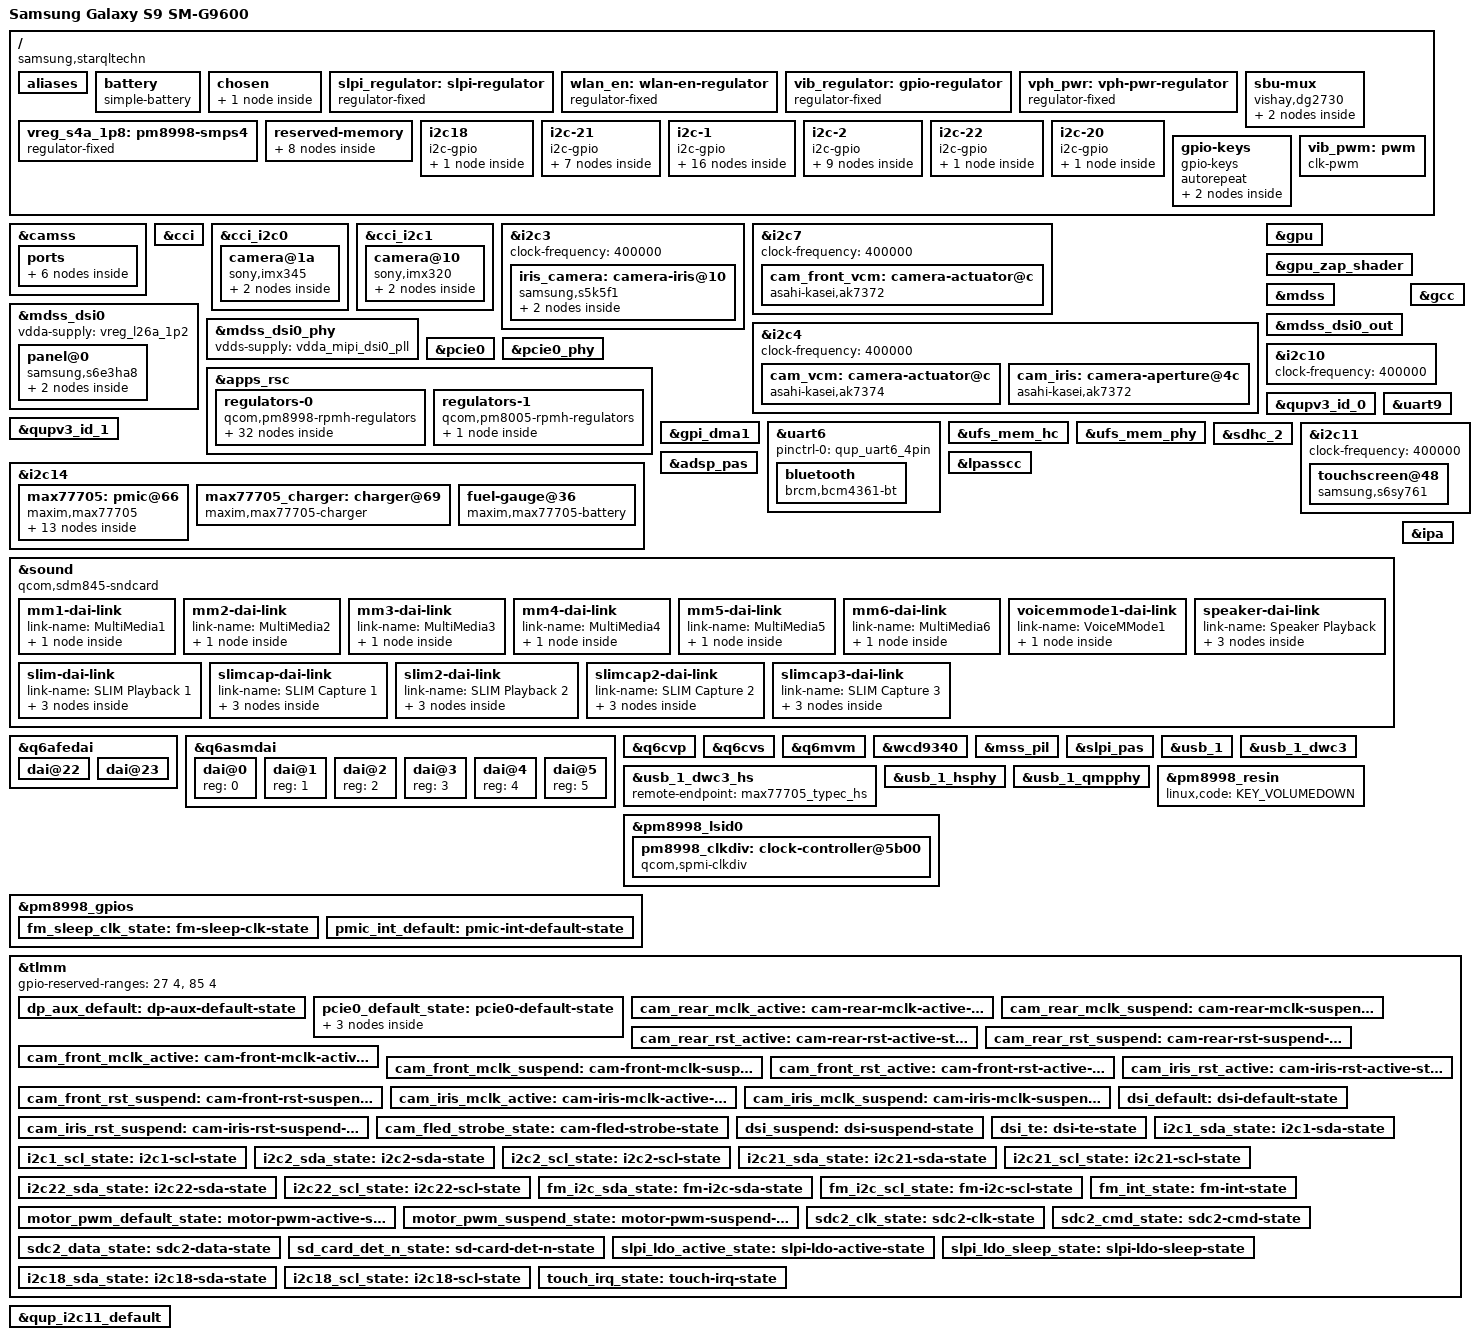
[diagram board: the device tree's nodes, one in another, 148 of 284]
// SPDX-License-Identifier: GPL-2.0
/*
 * SDM845 Samsung S9 (SM-G9600) (starqltechn / star2qltechn) common device tree source
 *
 * Copyright (c) 2020, The Linux Foundation. All rights reserved.
 */

/dts-v1/;

#include <dt-bindings/input/linux-event-codes.h>
#include <dt-bindings/gpio/gpio.h>
#include <dt-bindings/leds/common.h>
#include <dt-bindings/media/video-interfaces.h>
#include <dt-bindings/regulator/qcom,rpmh-regulator.h>
#include <dt-bindings/sound/qcom,q6afe.h>
#include <dt-bindings/sound/qcom,q6asm.h>
#include <dt-bindings/sound/qcom,wcd934x.h>
#include <dt-bindings/sound/qcom,q6voice.h>

#include "sdm845.dtsi"
#include "pm8998.dtsi"
#include "sdm845-wcd9340.dtsi"

/delete-node/ &rmtfs_mem;
/delete-node/ &spss_mem;
/delete-node/ &adsp_mem;

/ {
	chassis-type = "handset";
	model = "Samsung Galaxy S9 SM-G9600";
	compatible = "samsung,starqltechn", "qcom,sdm845";

	aliases {
		serial0 = &uart9;
		serial1 = &uart6;
	};

	battery: battery {
		compatible = "simple-battery";
		constant-charge-current-max-microamp = <2150000>;
		charge-full-design-microamp-hours = <3000000>;

		over-voltage-threshold-microvolt = <4500000>;
		voltage-min-design-microvolt = <3400000>;
		voltage-max-design-microvolt = <4350000>;
	};

	chosen {
		#address-cells = <2>;
		#size-cells = <2>;
		ranges;

		framebuffer: framebuffer-0 {
			compatible = "simple-framebuffer";
			memory-region = <&framebuffer_mem>;
			width = <1440>;
			height = <2960>;
			stride = <(1440 * 4)>;
			format = "a8r8g8b8";
			vci-supply = <&s2dos05_ldo4>;
			vddr-supply = <&s2dos05_buck>;
			vdd3-supply = <&s2dos05_ldo1>;
		};
	};

	slpi_regulator: slpi-regulator {
		compatible = "regulator-fixed";
		pinctrl-0 = <&slpi_ldo_active_state>;
		pinctrl-names = "default";

		regulator-always-on;
		regulator-boot-on;
		regulator-min-microvolt = <1800000>;
		regulator-max-microvolt = <1800000>;
		regulator-name = "slpi";

		enable-active-high;
		gpio = <&tlmm 8 GPIO_ACTIVE_HIGH>;
	};

	wlan_en: wlan-en-regulator {
		compatible = "regulator-fixed";

		regulator-name = "wlan-en";
		regulator-min-microvolt = <3300000>;
		regulator-max-microvolt = <3300000>;

		enable-active-high;
		gpio = <&tlmm 99 GPIO_ACTIVE_HIGH>;
		startup-delay-us = <200000>;
	};

	vib_regulator: gpio-regulator {
		compatible = "regulator-fixed";

		regulator-name = "haptic";
		regulator-min-microvolt = <1800000>;
		regulator-max-microvolt = <1800000>;

		gpio = <&pm8998_gpios 18 GPIO_ACTIVE_HIGH>;
		enable-active-high;

		regulator-boot-on;
	};

	vph_pwr: vph-pwr-regulator {
		compatible = "regulator-fixed";
		regulator-name = "vph_pwr";
		regulator-min-microvolt = <3700000>;
		regulator-max-microvolt = <3700000>;
	};

	/*
	 * Steers the SBU pair onto the DisplayPort AUX lines, so that AUX
	 * follows the cable orientation. The vendor kernel calls this the EDP
	 * AUX switch and drives the enable low to connect it.
	 */
	sbu-mux {
		compatible = "vishay,dg2730", "gpio-sbu-mux";

		enable-gpios = <&tlmm 7 GPIO_ACTIVE_LOW>;
		select-gpios = <&tlmm 100 GPIO_ACTIVE_HIGH>;

		pinctrl-0 = <&dp_aux_default>;
		pinctrl-names = "default";

		mode-switch;
		orientation-switch;

		port {
			sbu_mux_in: endpoint {
				remote-endpoint = <&max77705_typec_sbu>;
			};
		};
	};

	/*
	 * Apparently RPMh does not provide support for PM8998 S4 because it
	 * is always-on; model it as a fixed regulator.
	 */
	vreg_s4a_1p8: pm8998-smps4 {
		compatible = "regulator-fixed";
		regulator-name = "vreg_s4a_1p8";

		regulator-min-microvolt = <1800000>;
		regulator-max-microvolt = <1800000>;

		regulator-always-on;
		regulator-boot-on;

		vin-supply = <&vph_pwr>;
	};

	reserved-memory {
		framebuffer_mem: memory@9d400000 {
			reg = <0x0 0x9d400000 0x0 0x02400000>;
			no-map;
		};

		memory@a1300000 {
			compatible = "ramoops";
			reg = <0x0 0xa1300000 0x0 0x100000>;
			record-size = <0x40000>;
			console-size = <0x40000>;
			ftrace-size = <0x40000>;
			pmsg-size = <0x40000>;
		};

		/*
		 * It seems like reserving the old rmtfs_mem region is also needed to prevent
		 * random crashes which are most likely modem related, more testing needed.
		 */
		removed_region: removed-region@88f00000 {
			reg = <0 0x88f00000 0 0x1c00000>;
			no-map;
		};

		/*
		 * This device gives SLPI 16 MiB rather than the SoC default of
		 * 20 MiB, and puts SPSS directly after it. Without shrinking
		 * SLPI to match, the two regions overlap and the kernel says so
		 * at boot.
		 */
		slpi_mem: slpi@96700000 {
			reg = <0 0x96700000 0 0x1000000>;
			no-map;
		};

		spss_mem: spss@97700000 {
			reg = <0 0x97700000 0 0x100000>;
			no-map;
		};

		fb_mem: memory@95800000 {
			reg = <0 0x95800000 0 0x500000>;
			no-map;
		};

		adsp_mem: memory@97800000 {
			reg = <0 0x97800000 0 0x2000000>;
			no-map;
		};

		rmtfs_mem: rmtfs-mem@fde00000 {
			compatible = "qcom,rmtfs-mem";
			reg = <0 0xfde00000 0 0x202000>;
			qcom,use-guard-pages;
			no-map;

			qcom,client-id = <1>;
			qcom,vmid = <QCOM_SCM_VMID_MSS_MSA>;
		};
	};

	i2c18 {
		compatible = "i2c-gpio";
		sda-gpios = <&tlmm 62 GPIO_ACTIVE_HIGH>;
		scl-gpios = <&tlmm 63 GPIO_ACTIVE_HIGH>;
		i2c-gpio,delay-us = <2>;
		pinctrl-0 = <&i2c18_sda_state &i2c18_scl_state>;
		pinctrl-names = "default";
		#address-cells = <1>;
		#size-cells = <0>;

		max98512_codec: max98512@39 {
			compatible = "maxim,max98512";
			#sound-dai-cells = <0>;
			reg = <0x39>;
			maxim,spk-gain = <0x5>;
			maxim,spk-gain-rcv = <0x1>;
			maxim,digital-gain-rcv = <0x34>;
			maxim,sysclk = <0xbb8000>;
			maxim,vmon_slot = <0x1>;
			maxim,platform_info = <0x1 0x1006 0x10001062 0x1ff1020b 0x0 0x33>;
			maxim,boost_step = <0xf 0xf 0xf 0xf 0xf 0xf 0xf 0xf 0xf 0xf 0xf 0xf 0xf 0xf 0x2 0x0>;
			maxim,registers-of-amp = <0x1f 0x0 0x21 0xc0 0x2d 0x14 0x2f 0x0>;
			maxim,sub_reg = <0x3a>;
			maxim,mono_stereo = <0x1>;
			interleave_mode = <0x1>;
		};
	};

	i2c-21 {
		compatible = "i2c-gpio";
		sda-gpios = <&tlmm 127 (GPIO_ACTIVE_HIGH | GPIO_OPEN_DRAIN)>;
		scl-gpios = <&tlmm 128 (GPIO_ACTIVE_HIGH | GPIO_OPEN_DRAIN)>;
		i2c-gpio,delay-us = <2>;
		pinctrl-0 = <&i2c21_sda_state &i2c21_scl_state>;
		pinctrl-names = "default";
		#address-cells = <1>;
		#size-cells = <0>;

		pmic@60 {
			compatible = "samsung,s2dos05";
			reg = <0x60>;

			regulators {
				s2dos05_ldo1: ldo1 {
					regulator-active-discharge = <1>;
					regulator-enable-ramp-delay = <12000>;
					regulator-min-microvolt = <1500000>;
					regulator-max-microvolt = <2000000>;
					regulator-name = "ldo1";
				};

				s2dos05_ldo2: ldo2 {
					regulator-active-discharge = <1>;
					regulator-boot-on;
					regulator-enable-ramp-delay = <12000>;
					regulator-min-microvolt = <1800000>;
					regulator-max-microvolt = <1800000>;
					regulator-name = "ldo2";
				};

				s2dos05_ldo3: ldo3 {
					regulator-active-discharge = <1>;
					regulator-boot-on;
					regulator-enable-ramp-delay = <12000>;
					regulator-min-microvolt = <3000000>;
					regulator-max-microvolt = <3000000>;
					regulator-name = "ldo3";
				};

				s2dos05_ldo4: ldo4 {
					regulator-active-discharge = <1>;
					regulator-enable-ramp-delay = <12000>;
					regulator-min-microvolt = <2700000>;
					regulator-max-microvolt = <3775000>;
					regulator-name = "ldo4";
				};

				s2dos05_buck: buck {
					regulator-active-discharge = <1>;
					regulator-enable-ramp-delay = <12000>;
					regulator-min-microvolt = <850000>;
					regulator-max-microvolt = <2100000>;
					regulator-name = "buck";
				};
			};
		};
	};

	/*
	 * Front camera sub-PMIC bus. The s2mpb02 also carries two rails for
	 * the rear camera's actuator and OIS, plus a flash/torch LED
	 * controller that is not modelled yet.
	 *
	 * Only the rails with known camera consumers are described. The
	 * bucks and buck-boost feed loads that have not been identified, and
	 * declaring a fixed voltage for them would make the regulator core
	 * reprogram whatever the bootloader left in place.
	 */
	i2c-1 {
		compatible = "i2c-gpio";
		sda-gpios = <&tlmm 23 (GPIO_ACTIVE_HIGH | GPIO_OPEN_DRAIN)>;
		scl-gpios = <&tlmm 24 (GPIO_ACTIVE_HIGH | GPIO_OPEN_DRAIN)>;
		i2c-gpio,delay-us = <2>;
		pinctrl-0 = <&i2c1_sda_state &i2c1_scl_state>;
		pinctrl-names = "default";
		#address-cells = <1>;
		#size-cells = <0>;

		pmic@59 {
			compatible = "samsung,s2mpb02";
			reg = <0x59>;

			/*
			 * Both FLED channels are driven over I2C, so hold the
			 * three external strobe pins low: FLASH_EN1 (gpio22)
			 * and TORCH_EN1 (gpio21) for the rear flash, and
			 * IRIS_EN (gpio43) for the illuminator. The vendor
			 * asserts IRIS_EN for the whole iris session and lets
			 * the pulse-width registers shape the light, which is
			 * the fallback if I2C strobing alone does not light it.
			 */
			pinctrl-0 = <&cam_fled_strobe_state>;
			pinctrl-names = "default";

			/*
			 * Currents and timeouts are the ones the vendor
			 * programs: 1000mA/500ms flash and 180mA torch on the
			 * rear LED, 500mA/250ms and 300mA on the illuminator.
			 */
			leds {
				#address-cells = <1>;
				#size-cells = <0>;

				s2mpb02_flash: led@0 {
					reg = <0>;
					color = <LED_COLOR_ID_WHITE>;
					function = LED_FUNCTION_FLASH;
					led-max-microamp = <180000>;
					flash-max-microamp = <1000000>;
					flash-max-timeout-us = <500000>;
				};

				/*
				 * Deliberately not LED_FUNCTION_FLASH: mobile
				 * shells look for a flashlight by matching LED
				 * class names against *:flash* and *:torch*,
				 * and this one emits infrared. Naming it
				 * "flash" makes the shell offer an invisible
				 * torch that only drains the battery.
				 */
				s2mpb02_ir: led@1 {
					reg = <1>;
					color = <LED_COLOR_ID_IR>;
					function = "illuminator";
					led-max-microamp = <300000>;
					flash-max-microamp = <500000>;
					flash-max-timeout-us = <250000>;
				};
			};

			regulators {
				s2mpb02_l5: ldo5 {
					regulator-name = "cam_front_vdig";
					regulator-min-microvolt = <1050000>;
					regulator-max-microvolt = <1050000>;
				};

				s2mpb02_l6: ldo6 {
					regulator-name = "cam_front_vio";
					regulator-min-microvolt = <1800000>;
					regulator-max-microvolt = <1800000>;
				};

				s2mpb02_l10: ldo10 {
					regulator-name = "cam_v_custom3";
					regulator-min-microvolt = <1800000>;
					regulator-max-microvolt = <1800000>;
				};

				s2mpb02_l13: ldo13 {
					regulator-name = "cam_front_vana";
					regulator-min-microvolt = <2800000>;
					regulator-max-microvolt = <2800000>;
				};

				s2mpb02_l14: ldo14 {
					regulator-name = "cam_vaf";
					regulator-min-microvolt = <3300000>;
					regulator-max-microvolt = <3300000>;
				};

				s2mpb02_l15: ldo15 {
					regulator-name = "cam_v_custom4";
					regulator-min-microvolt = <2800000>;
					regulator-max-microvolt = <2800000>;
				};

				s2mpb02_l16: ldo16 {
					regulator-name = "cam_front_vaf";
					regulator-min-microvolt = <2800000>;
					regulator-max-microvolt = <2800000>;
				};

				s2mpb02_l17: ldo17 {
					regulator-name = "cam_iris_vana";
					regulator-min-microvolt = <2800000>;
					regulator-max-microvolt = <2800000>;
				};

				/*
				 * BUCK1, BUCK2 and the buck-boost are the input
				 * rails the LDOs above regulate down from, so
				 * they have no consumer of their own and must
				 * stay on. The bootloader leaves them in
				 * pin-controlled mode at voltages that do not
				 * match the ones the vendor uses, so declare
				 * them here and let the core program them.
				 */
				s2mpb02_b1: buck1 {
					regulator-name = "cam_buck1";
					regulator-min-microvolt = <1300000>;
					regulator-max-microvolt = <1300000>;
					regulator-always-on;
				};

				s2mpb02_b2: buck2 {
					regulator-name = "cam_buck2";
					regulator-min-microvolt = <1300000>;
					regulator-max-microvolt = <1300000>;
					regulator-always-on;
				};

				s2mpb02_bb: bb {
					regulator-name = "cam_buckboost";
					regulator-min-microvolt = <3500000>;
					regulator-max-microvolt = <3500000>;
					regulator-always-on;
				};
			};
		};
	};

	/*
	 * Camera sub-PMIC bus. Supplies the rear camera rails; the sensor
	 * itself additionally draws two rails from the s2mpb02 on another
	 * bus, which are only needed for the actuator and OIS.
	 */
	i2c-2 {
		compatible = "i2c-gpio";
		sda-gpios = <&tlmm 11 (GPIO_ACTIVE_HIGH | GPIO_OPEN_DRAIN)>;
		scl-gpios = <&tlmm 74 (GPIO_ACTIVE_HIGH | GPIO_OPEN_DRAIN)>;
		i2c-gpio,delay-us = <2>;
		pinctrl-0 = <&i2c2_sda_state &i2c2_scl_state>;
		pinctrl-names = "default";
		#address-cells = <1>;
		#size-cells = <0>;

		pmic@56 {
			compatible = "samsung,s2mpb03";
			reg = <0x56>;

			regulators {
				s2mpb03_l1: ldo1 {
					regulator-name = "cam_vdig";
					regulator-min-microvolt = <1000000>;
					regulator-max-microvolt = <1000000>;
				};

				s2mpb03_l2: ldo2 {
					regulator-name = "cam_v_custom2";
					regulator-min-microvolt = <1100000>;
					regulator-max-microvolt = <1100000>;
					regulator-active-discharge = <1>;
				};

				s2mpb03_l3: ldo3 {
					regulator-name = "cam_vio";
					regulator-min-microvolt = <1800000>;
					regulator-max-microvolt = <1800000>;
				};

				s2mpb03_l4: ldo4 {
					regulator-name = "cam_v_custom10";
					regulator-min-microvolt = <1100000>;
					regulator-max-microvolt = <1100000>;
				};

				s2mpb03_l5: ldo5 {
					regulator-name = "cam_vana";
					regulator-min-microvolt = <3200000>;
					regulator-max-microvolt = <3200000>;
					regulator-soft-start;
				};

				s2mpb03_l6: ldo6 {
					regulator-name = "cam_v_custom1";
					regulator-min-microvolt = <2850000>;
					regulator-max-microvolt = <2850000>;
					regulator-soft-start;
				};

				s2mpb03_l7: ldo7 {
					regulator-name = "cam_v_custom5";
					regulator-min-microvolt = <2800000>;
					regulator-max-microvolt = <2800000>;
				};
			};
		};
	};

	/*
	 * GPIO expander bus. The PCAL6524 carries board control lines that are
	 * not routed to the SoC: the microSD and NFC enables, wireless charging
	 * and MST power, the fingerprint sensor's LDO and reset, and the
	 * heart-rate sensor's boost enable.
	 */
	i2c-22 {
		compatible = "i2c-gpio";
		sda-gpios = <&tlmm 123 (GPIO_ACTIVE_HIGH | GPIO_OPEN_DRAIN)>;
		scl-gpios = <&tlmm 124 (GPIO_ACTIVE_HIGH | GPIO_OPEN_DRAIN)>;
		i2c-gpio,delay-us = <2>;
		pinctrl-0 = <&i2c22_sda_state &i2c22_scl_state>;
		pinctrl-names = "default";
		#address-cells = <1>;
		#size-cells = <0>;

		gpio_expander: gpio@22 {
			compatible = "nxp,pcal6524";
			reg = <0x22>;

			gpio-controller;
			#gpio-cells = <2>;

			reset-gpios = <&tlmm 69 GPIO_ACTIVE_LOW>;
			vcc-supply = <&vreg_s4a_1p8>;

			gpio-line-names = "microsd-en", "", "", "wireless-charger-en",
					  "mst-pwr-en", "", "nfc-en", "nfc-firmware",
					  "", "", "", "",
					  "", "", "", "",
					  "", "", "fingerprint-ldo-en", "",
					  "fingerprint-reset", "", "fingerprint-vendor-id",
					  "hrm-boost-en";
		};
	};

	/*
	 * FM tuner bus. The Richwave RTC6213N takes its 32.768 kHz reference
	 * from pm8998 GPIO13 in func1 (sleep clock) mode, so that state is
	 * applied here alongside the bus pins -- the tuner does not answer
	 * without its clock running.
	 */
	i2c-20 {
		compatible = "i2c-gpio";
		sda-gpios = <&tlmm 103 GPIO_ACTIVE_HIGH>;
		scl-gpios = <&tlmm 104 GPIO_ACTIVE_HIGH>;
		i2c-gpio,delay-us = <2>;
		pinctrl-0 = <&fm_i2c_sda_state &fm_i2c_scl_state &fm_sleep_clk_state>;
		pinctrl-names = "default";
		#address-cells = <1>;
		#size-cells = <0>;

		tuner@64 {
			compatible = "richwave,rtc6213n";
			reg = <0x64>;

			interrupts-extended = <&tlmm 145 IRQ_TYPE_EDGE_FALLING>;
			pinctrl-0 = <&fm_int_state>;
			pinctrl-names = "default";

			/*
			 * BRING-UP: which of the three dividers actually lands
			 * on PMIC GPIO13 is not documented anywhere we have,
			 * so claim all three and let the driver enable them.
			 * Narrow this to the one that matters once the core
			 * comes up.
			 */
			clocks = <&pm8998_clkdiv 1>, <&pm8998_clkdiv 2>,
				 <&pm8998_clkdiv 3>;
			clock-names = "div1", "div2", "div3";
		};
	};

	gpio-keys {
		compatible = "gpio-keys";
		autorepeat;

		key-vol-up {
			label = "Volume Up";
			gpios = <&pm8998_gpios 6 GPIO_ACTIVE_LOW>;
			linux,code = <KEY_VOLUMEUP>;
			debounce-interval = <15>;
		};

		key-wink {
			label = "Bixby";
			gpios = <&pm8998_gpios 19 GPIO_ACTIVE_LOW>;
			linux,code = <KEY_ENTER>;
			debounce-interval = <15>;
		};
	};

	vib_pwm: pwm {
		compatible = "clk-pwm";
		#pwm-cells = <2>;
		assigned-clock-parents = <&rpmhcc RPMH_CXO_CLK>;
		assigned-clocks = <&gcc GCC_GP1_CLK_SRC>;
		clocks = <&gcc GCC_GP1_CLK>;
		pinctrl-0 = <&motor_pwm_default_state>;
		pinctrl-1 = <&motor_pwm_suspend_state>;
		pinctrl-names = "default", "suspend";
	};
};

&camss {
	vdda-phy-supply = <&vreg_l1a_0p875>;
	vdda-pll-supply = <&vreg_l26a_1p2>;

	status = "okay";

	ports {
		#address-cells = <1>;
		#size-cells = <0>;

		port@0 {
			reg = <0>;

			csiphy0_ep: endpoint {
				bus-type = <MEDIA_BUS_TYPE_CSI2_DPHY>;
				data-lanes = <0 1 2 3>;
				remote-endpoint = <&imx345_ep>;
			};
		};

		port@2 {
			reg = <2>;

			csiphy2_ep: endpoint {
				bus-type = <MEDIA_BUS_TYPE_CSI2_DPHY>;
				data-lanes = <0 1>;
				remote-endpoint = <&imx320_ep>;
			};
		};

		port@3 {
			reg = <3>;

			csiphy3_ep: endpoint {
				bus-type = <MEDIA_BUS_TYPE_CSI2_DPHY>;
				data-lanes = <0 1>;
				remote-endpoint = <&s5k5f1_ep>;
			};
		};
	};
};

&cci {
	status = "okay";
};

&cci_i2c0 {
	/* Rear camera, Sony IMX345 12MP */
	camera@1a {
		compatible = "sony,imx345";
		reg = <0x1a>;

		clocks = <&clock_camcc CAM_CC_MCLK0_CLK>;
		assigned-clocks = <&clock_camcc CAM_CC_MCLK0_CLK>;
		assigned-clock-rates = <24000000>;
		power-domains = <&clock_camcc TITAN_TOP_GDSC>;

		vio-supply = <&s2mpb03_l3>;
		vdig-supply = <&s2mpb03_l1>;
		vcustom1-supply = <&s2mpb03_l6>;
		vcustom2-supply = <&s2mpb03_l2>;
		vana-supply = <&s2mpb03_l5>;
		vcustom10-supply = <&s2mpb03_l4>;

		reset-gpios = <&tlmm 25 GPIO_ACTIVE_LOW>;
		lens-focus = <&cam_vcm>;
		lens-iris = <&cam_iris>;
		flash-leds = <&s2mpb02_flash>;

		pinctrl-0 = <&cam_rear_mclk_active &cam_rear_rst_active>;
		pinctrl-1 = <&cam_rear_mclk_suspend &cam_rear_rst_suspend>;
		pinctrl-names = "default", "sleep";

		orientation = <1>;
		rotation = <270>;

		port {
			imx345_ep: endpoint {
				remote-endpoint = <&csiphy0_ep>;
				data-lanes = <1 2 3 4>;
				link-frequencies = /bits/ 64 <675000000 702000000>;
			};
		};
	};
};

&cci_i2c1 {
	/* Front camera, Sony IMX320 8MP */
	camera@10 {
		compatible = "sony,imx320";
		reg = <0x10>;

		clocks = <&clock_camcc CAM_CC_MCLK2_CLK>;
		assigned-clocks = <&clock_camcc CAM_CC_MCLK2_CLK>;
		assigned-clock-rates = <24000000>;
		power-domains = <&clock_camcc TITAN_TOP_GDSC>;

		vana-supply = <&s2mpb02_l13>;
		vio-supply = <&s2mpb02_l6>;
		vcore-supply = <&s2mpb02_l5>;

		reset-gpios = <&tlmm 12 GPIO_ACTIVE_LOW>;
		lens-focus = <&cam_front_vcm>;

		pinctrl-0 = <&cam_front_mclk_active &cam_front_rst_active>;
		pinctrl-1 = <&cam_front_mclk_suspend &cam_front_rst_suspend>;
		pinctrl-names = "default", "sleep";

		orientation = <0>;
		rotation = <90>;

		port {
			imx320_ep: endpoint {
				remote-endpoint = <&csiphy2_ep>;
				data-lanes = <1 2>;
				link-frequencies = /bits/ 64 <172500000 681000000
							      738000000>;
			};
		};
	};
};

&i2c3 {
	clock-frequency = <400000>;
	status = "okay";

	/*
	 * Iris camera, Samsung S5K5F1 5.7MP monochrome infrared.
	 *
	 * The control bus is QUP SE3, not the CCI: the stock DTB has this
	 * sensor as a child of i2c@88c000, sharing the bus with the NFC
	 * controller, while the other three sensors hang off the CCI. Only the
	 * CSI-2 side is camera hardware - CSIPHY3, wired below. The stock DTB
	 * spells the address 0x20, which is the 8-bit form of 7-bit 0x10.
	 *
	 * Because the control bus is separate there is no address clash with
	 * the front camera, which answers at the same 0x10 on the CCI, and both
	 * can be enabled at once. Stock streams the two together for the
	 * duration of an iris session.
	 */
	iris_camera: camera-iris@10 {
		compatible = "samsung,s5k5f1";
		reg = <0x10>;

		clocks = <&clock_camcc CAM_CC_MCLK3_CLK>;
		assigned-clocks = <&clock_camcc CAM_CC_MCLK3_CLK>;
		assigned-clock-rates = <24000000>;
		power-domains = <&clock_camcc TITAN_TOP_GDSC>;

		vio-supply = <&vreg_l19a_1p8>;
		vdig-supply = <&vreg_l17a_1p05>;
		vana-supply = <&s2mpb02_l17>;

		reset-gpios = <&tlmm 44 GPIO_ACTIVE_LOW>;

		flash-leds = <&s2mpb02_ir>;

		pinctrl-0 = <&cam_iris_mclk_active &cam_iris_rst_active>;
		pinctrl-1 = <&cam_iris_mclk_suspend &cam_iris_rst_suspend>;
		pinctrl-names = "default", "sleep";

		orientation = <0>;
		/* From the stock DT's sensor-position-roll; not verified */
		rotation = <0>;

		port {
			s5k5f1_ep: endpoint {
				remote-endpoint = <&csiphy3_ep>;
				data-lanes = <1 2>;
				link-frequencies = /bits/ 64 <768000000>;
			};
		};
	};
};

&i2c7 {
	/*
	 * Front camera focus actuator. The stock DT also puts the front
	 * module's EEPROM at 0x51 on this bus; it has no mainline consumer.
	 */
	clock-frequency = <400000>;

	status = "okay";

	cam_front_vcm: camera-actuator@c {
		compatible = "asahi-kasei,ak7372";
		reg = <0x0c>;

		vdd-supply = <&s2mpb02_l16>;
		vio-supply = <&s2mpb02_l6>;
	};
};

&i2c4 {
	/*
	 * Rear camera focus actuator, plus the OIS at 0x48 and the aperture
	 * motor at 0x4c, neither of which has a mainline driver yet.
	 */
	clock-frequency = <400000>;

	status = "okay";

	cam_vcm: camera-actuator@c {
		compatible = "asahi-kasei,ak7374";
		reg = <0x0c>;

		vdd-supply = <&s2mpb02_l14>;
		vio-supply = <&s2mpb02_l10>;
	};

	/*
	 * Samsung's Dual Aperture blades, driven by a second AK7372 sharing
	 * the focus actuator's rails. The mechanism selects f/1.5 or f/2.4;
	 * the codes that move it are not known yet, so the blades do not
	 * actually travel, but the control plumbing is real.
	 */
	cam_iris: camera-aperture@4c {
		compatible = "asahi-kasei,ak7372";
		reg = <0x4c>;

		asahi-kasei,iris;

		vdd-supply = <&s2mpb02_l14>;
		vio-supply = <&s2mpb02_l10>;
	};
};

&gpu {
	status = "okay";
};

&gpu_zap_shader {
	firmware-name = "qcom/sdm845/Samsung/starqltechn/a630_zap.mbn";
};

&mdss {
	status = "okay";
};

&mdss_dsi0 {
	vdda-supply = <&vreg_l26a_1p2>;
	status = "okay";

	panel@0 {
		compatible = "samsung,s6e3ha8";
		reg = <0>;
		vci-supply = <&s2dos05_ldo4>;
		vddr-supply = <&s2dos05_buck>;
		vdd3-supply = <&s2dos05_ldo1>;
		te-gpios = <&tlmm 10 GPIO_ACTIVE_HIGH>;
		reset-gpios = <&tlmm 6 GPIO_ACTIVE_HIGH>;
		pinctrl-0 = <&dsi_default &dsi_te>;
		pinctrl-1 = <&dsi_suspend &dsi_te>;
		pinctrl-names = "default", "suspend";

		port {
			panel_in: endpoint {
				remote-endpoint = <&mdss_dsi0_out>;
			};
		};
	};
};

&mdss_dsi0_out {
	data-lanes = <0 1 2 3>;
	remote-endpoint = <&panel_in>;
};

&mdss_dsi0_phy {
	vdds-supply = <&vdda_mipi_dsi0_pll>;
	status = "okay";
};

&pcie0 {
	perst-gpios = <&tlmm 35 GPIO_ACTIVE_LOW>;
	wake-gpios = <&tlmm 116 GPIO_ACTIVE_HIGH>;

	vddpe-3v3-supply = <&wlan_en>;

	pinctrl-names = "default";
	pinctrl-0 = <&pcie0_default_state>;

	status = "okay";
};

&pcie0_phy {
	vdda-phy-supply = <&vdda_pcie_core>;
	vdda-pll-supply = <&vdda_pcie_1p2>;

	status = "okay";
};

&apps_rsc {
	regulators-0 {
		compatible = "qcom,pm8998-rpmh-regulators";
		qcom,pmic-id = "a";

		vdd-s1-supply = <&vph_pwr>;
		vdd-s2-supply = <&vph_pwr>;
		vdd-s3-supply = <&vph_pwr>;
		vdd-s4-supply = <&vph_pwr>;
		vdd-s5-supply = <&vph_pwr>;
		vdd-s6-supply = <&vph_pwr>;
		vdd-s7-supply = <&vph_pwr>;
		vdd-s8-supply = <&vph_pwr>;
		vdd-s9-supply = <&vph_pwr>;
		vdd-s10-supply = <&vph_pwr>;
		vdd-s11-supply = <&vph_pwr>;
		vdd-s12-supply = <&vph_pwr>;
		vdd-s13-supply = <&vph_pwr>;
		vdd-l1-l27-supply = <&vreg_s7a_1p025>;
		vdd-l2-l8-l17-supply = <&vreg_s3a_1p35>;
		vdd-l3-l11-supply = <&vreg_s7a_1p025>;
		vdd-l4-l5-supply = <&vreg_s7a_1p025>;
		vdd-l6-supply = <&vph_pwr>;
		vdd-l7-l12-l14-l15-supply = <&vreg_s5a_2p04>;
		vdd-l26-supply = <&vreg_s3a_1p35>;
		vin-lvs-1-2-supply = <&vreg_s4a_1p8>;

		vreg_s2a_1p125: smps2 {
			regulator-min-microvolt = <1100000>;
			regulator-max-microvolt = <1100000>;
		};

		vreg_s3a_1p35: smps3 {
			regulator-min-microvolt = <1352000>;
			regulator-max-microvolt = <1352000>;
		};

		vreg_s5a_2p04: smps5 {
			regulator-min-microvolt = <1904000>;
			regulator-max-microvolt = <2040000>;
		};

		vreg_s7a_1p025: smps7 {
			regulator-min-microvolt = <900000>;
			regulator-max-microvolt = <1028000>;
		};

		vdd_qusb_hs0:
		vdda_hp_pcie_core:
		vdda_mipi_csi0_0p9:
		vdda_mipi_csi1_0p9:
		vdda_mipi_csi2_0p9:
		vdda_mipi_dsi0_pll:
		vdda_mipi_dsi1_pll:
		vdda_qlink_lv:
		vdda_qlink_lv_ck:
		vdda_qrefs_0p875:
		vdda_pcie_core:
		vdda_pll_cc_ebi01:
		vdda_pll_cc_ebi23:
		vdda_sp_sensor:
		vdda_ufs1_core:
		vdda_ufs2_core:
		vreg_l1a_0p875: ldo1 {
			regulator-min-microvolt = <880000>;
			regulator-max-microvolt = <880000>;
			regulator-initial-mode = <RPMH_REGULATOR_MODE_HPM>;
		};

		vddpx_10:
		vreg_l2a_1p2: ldo2 {
			regulator-min-microvolt = <1200000>;
			regulator-max-microvolt = <1200000>;
			regulator-initial-mode = <RPMH_REGULATOR_MODE_HPM>;
			regulator-always-on;
		};

		vreg_l3a_1p0: ldo3 {
			regulator-min-microvolt = <1000000>;
			regulator-max-microvolt = <1000000>;
			regulator-initial-mode = <RPMH_REGULATOR_MODE_HPM>;
		};

		vdda_usb1_ss_core:
		vdd_wcss_cx:
		vdd_wcss_mx:
		vdda_wcss_pll:
		vreg_l5a_0p8: ldo5 {
			regulator-min-microvolt = <800000>;
			regulator-max-microvolt = <800000>;
			regulator-initial-mode = <RPMH_REGULATOR_MODE_HPM>;
		};

		vddpx_13:
		vreg_l6a_1p8: ldo6 {
			regulator-min-microvolt = <1856000>;
			regulator-max-microvolt = <1856000>;
			regulator-initial-mode = <RPMH_REGULATOR_MODE_HPM>;
		};

		vreg_l7a_1p8: ldo7 {
			regulator-min-microvolt = <1800000>;
			regulator-max-microvolt = <1800000>;
			regulator-initial-mode = <RPMH_REGULATOR_MODE_HPM>;
		};

		vreg_l8a_1p2: ldo8 {
			regulator-min-microvolt = <1200000>;
			regulator-max-microvolt = <1248000>;
			regulator-initial-mode = <RPMH_REGULATOR_MODE_HPM>;
		};

		vreg_l9a_1p8: ldo9 {
			regulator-min-microvolt = <1704000>;
			regulator-max-microvolt = <2928000>;
			regulator-initial-mode = <RPMH_REGULATOR_MODE_HPM>;
		};

		vreg_l10a_1p8: ldo10 {
			regulator-min-microvolt = <1704000>;
			regulator-max-microvolt = <2928000>;
			regulator-initial-mode = <RPMH_REGULATOR_MODE_HPM>;
		};

		vreg_l11a_1p0: ldo11 {
			regulator-min-microvolt = <1000000>;
			regulator-max-microvolt = <1048000>;
			regulator-initial-mode = <RPMH_REGULATOR_MODE_HPM>;
		};

		vdd_qfprom:
		vdd_qfprom_sp:
		vdda_apc1_cs_1p8:
		vdda_gfx_cs_1p8:
		vdda_qrefs_1p8:
		vdda_qusb_hs0_1p8:
		vddpx_11:
		vreg_l12a_1p8: ldo12 {
			regulator-min-microvolt = <1800000>;
			regulator-max-microvolt = <1800000>;
			regulator-initial-mode = <RPMH_REGULATOR_MODE_HPM>;
		};

		vddpx_2:
		vreg_l13a_2p95: ldo13 {
			regulator-min-microvolt = <1800000>;
			regulator-max-microvolt = <2960000>;
			regulator-initial-mode = <RPMH_REGULATOR_MODE_HPM>;
		};

		vreg_l14a_1p88: ldo14 {
			regulator-min-microvolt = <1800000>;
			regulator-max-microvolt = <1800000>;
			regulator-initial-mode = <RPMH_REGULATOR_MODE_HPM>;
		};

		vreg_l15a_1p8: ldo15 {
			regulator-min-microvolt = <1800000>;
			regulator-max-microvolt = <1800000>;
			regulator-initial-mode = <RPMH_REGULATOR_MODE_HPM>;
		};

		vreg_l16a_2p7: ldo16 {
			regulator-min-microvolt = <2704000>;
			regulator-max-microvolt = <2704000>;
			regulator-initial-mode = <RPMH_REGULATOR_MODE_HPM>;
		};

		/*
		 * Iris camera digital core. The vendor runs this rail at
		 * 1.05V, which falls between two steps of the PMIC4 NLDO's
		 * 8mV grid, so ask for the one below.
		 */
		vreg_l17a_1p05: ldo17 {
			regulator-min-microvolt = <1048000>;
			regulator-max-microvolt = <1048000>;
			regulator-initial-mode = <RPMH_REGULATOR_MODE_HPM>;
		};

		vreg_l18a_2p7: ldo18 {
			regulator-min-microvolt = <2704000>;
			regulator-max-microvolt = <2960000>;
			regulator-initial-mode = <RPMH_REGULATOR_MODE_HPM>;
		};

		/* Iris camera interface */
		vreg_l19a_1p8: ldo19 {
			regulator-min-microvolt = <1800000>;
			regulator-max-microvolt = <1800000>;
			regulator-initial-mode = <RPMH_REGULATOR_MODE_HPM>;
		};

		vreg_l20a_2p95: ldo20 {
			regulator-min-microvolt = <2704000>;
			regulator-max-microvolt = <2960000>;
			regulator-initial-mode = <RPMH_REGULATOR_MODE_HPM>;
		};

		vreg_l21a_2p95: ldo21 {
			regulator-min-microvolt = <2704000>;
			regulator-max-microvolt = <2960000>;
			regulator-initial-mode = <RPMH_REGULATOR_MODE_HPM>;
		};

		vreg_l22a_2p85: ldo22 {
			regulator-min-microvolt = <2864000>;
			regulator-max-microvolt = <3312000>;
			regulator-initial-mode = <RPMH_REGULATOR_MODE_HPM>;
		};

		vreg_l23a_3p3: ldo23 {
			regulator-min-microvolt = <3000000>;
			regulator-max-microvolt = <3312000>;
			regulator-initial-mode = <RPMH_REGULATOR_MODE_HPM>;
		};

		vdda_qusb_hs0_3p1:
		vreg_l24a_3p075: ldo24 {
			regulator-min-microvolt = <3088000>;
			regulator-max-microvolt = <3088000>;
			regulator-initial-mode = <RPMH_REGULATOR_MODE_HPM>;
		};

		vreg_l25a_3p3: ldo25 {
			regulator-min-microvolt = <3300000>;
			regulator-max-microvolt = <3312000>;
			regulator-initial-mode = <RPMH_REGULATOR_MODE_HPM>;
		};

		vdda_hp_pcie_1p2:
		vdda_hv_ebi0:
		vdda_hv_ebi1:
		vdda_hv_ebi2:
		vdda_hv_ebi3:
		vdda_mipi_csi_1p25:
		vdda_mipi_dsi0_1p2:
		vdda_mipi_dsi1_1p2:
		vdda_pcie_1p2:
		vdda_ufs1_1p2:
		vdda_ufs2_1p2:
		vdda_usb1_ss_1p2:
		vdda_usb2_ss_1p2:
		vreg_l26a_1p2: ldo26 {
			regulator-min-microvolt = <1200000>;
			regulator-max-microvolt = <1200000>;
			regulator-initial-mode = <RPMH_REGULATOR_MODE_HPM>;
		};

		vreg_l28a_3p0: ldo28 {
			regulator-min-microvolt = <2856000>;
			regulator-max-microvolt = <3008000>;
			regulator-initial-mode = <RPMH_REGULATOR_MODE_HPM>;
		};

		vreg_lvs1a_1p8: lvs1 {
			regulator-min-microvolt = <1800000>;
			regulator-max-microvolt = <1800000>;
		};

		vreg_lvs2a_1p8: lvs2 {
			regulator-min-microvolt = <1800000>;
			regulator-max-microvolt = <1800000>;
		};
	};

	regulators-1 {
		compatible = "qcom,pm8005-rpmh-regulators";
		qcom,pmic-id = "c";

		vdd-s1-supply = <&vph_pwr>;
		vdd-s2-supply = <&vph_pwr>;
		vdd-s3-supply = <&vph_pwr>;
		vdd-s4-supply = <&vph_pwr>;

		vreg_s3c_0p6: smps3 {
			regulator-min-microvolt = <600000>;
			regulator-max-microvolt = <600000>;
		};
	};
};

&gcc {
	protected-clocks = <GCC_QSPI_CORE_CLK>,
				<GCC_QSPI_CORE_CLK_SRC>,
				<GCC_QSPI_CNOC_PERIPH_AHB_CLK>,
				<GCC_LPASS_Q6_AXI_CLK>,
				<GCC_LPASS_SWAY_CLK>;
};

&i2c10 {
	clock-frequency = <400000>;
	status = "okay";
};

&qupv3_id_0 {
	status = "okay";
};

&qupv3_id_1 {
	status = "okay";
};

&gpi_dma1 {
	status = "okay";
};

&uart6 {
	pinctrl-0 = <&qup_uart6_4pin>;

	status = "okay";

	bluetooth {
		compatible = "brcm,bcm4361-bt";

		shutdown-gpios = <&pm8998_gpios 3 GPIO_ACTIVE_HIGH>;
		device-wakeup-gpios = <&tlmm 136 GPIO_ACTIVE_HIGH>;
		host-wakeup-gpios = <&tlmm 108 GPIO_ACTIVE_HIGH>;
	};
};

&uart9 {
	status = "okay";
};

&i2c14 {
	status = "okay";

	max77705: pmic@66 {
		compatible = "maxim,max77705";
		reg = <0x66>;
		#interrupt-cells = <1>;
		interrupt-parent = <&pm8998_gpios>;
		interrupts = <11 IRQ_TYPE_LEVEL_LOW>;
		interrupt-controller;
		pinctrl-0 = <&pmic_int_default>;
		pinctrl-names = "default";

		leds {
			compatible = "maxim,max77705-rgb";

			multi-led {
				color = <LED_COLOR_ID_RGB>;
				function = LED_FUNCTION_STATUS;
				#address-cells = <1>;
				#size-cells = <0>;

				led@1 {
					reg = <1>;
					color = <LED_COLOR_ID_RED>;
				};

				led@2 {
					reg = <2>;
					color = <LED_COLOR_ID_GREEN>;
				};

				led@3 {
					reg = <3>;
					color = <LED_COLOR_ID_BLUE>;
				};
			};
		};

		haptic {
			compatible = "maxim,max77705-haptic";
			haptic-supply = <&vib_regulator>;
			pwms = <&vib_pwm 0 52084>;
		};

		typec {
			compatible = "maxim,max77705-typec";
			interrupt-parent = <&max77705>;
			interrupts = <3>;
			orientation-switch;
			mode-switch;

			connector {
				compatible = "usb-c-connector";
				label = "USB-C";
				power-role = "dual";
				data-role = "dual";
				try-power-role = "sink";

				ports {
					#address-cells = <1>;
					#size-cells = <0>;

					port@0 {
						reg = <0>;

						max77705_typec_hs: endpoint {
							remote-endpoint = <&usb_1_dwc3_hs>;
						};
					};

					port@2 {
						reg = <2>;

						max77705_typec_sbu: endpoint {
							remote-endpoint = <&sbu_mux_in>;
						};
					};
				};
			};
		};
	};

	max77705_charger: charger@69 {
		reg = <0x69>;
		compatible = "maxim,max77705-charger";
		monitored-battery = <&battery>;
		interrupt-parent = <&max77705>;
		interrupts = <0>;
	};

	fuel-gauge@36 {
		reg = <0x36>;
		compatible = "maxim,max77705-battery";
		power-supplies = <&max77705_charger>;
		maxim,rsns-microohm = <5000>;
		interrupt-parent = <&max77705>;
		interrupts = <2>;
	};
};

&ufs_mem_hc {
	reset-gpios = <&tlmm 150 GPIO_ACTIVE_LOW>;
	vcc-supply = <&vreg_l20a_2p95>;
	vcc-max-microamp = <600000>;
	status = "okay";
};

&ufs_mem_phy {
	vdda-phy-supply = <&vdda_ufs1_core>;
	vdda-pll-supply = <&vdda_ufs1_1p2>;
	status = "okay";
};

&sdhc_2 {
	pinctrl-0 = <&sdc2_clk_state &sdc2_cmd_state &sdc2_data_state &sd_card_det_n_state>;
	pinctrl-names = "default";
	cd-gpios = <&tlmm 126 GPIO_ACTIVE_LOW>;
	vmmc-supply = <&vreg_l21a_2p95>;
	vqmmc-supply = <&vddpx_2>;
	status = "okay";
};

&i2c11 {
	clock-frequency = <400000>;
	status = "okay";

	touchscreen@48 {
		compatible = "samsung,s6sy761";
		reg = <0x48>;
		interrupt-parent = <&tlmm>;
		interrupts = <120 IRQ_TYPE_LEVEL_HIGH>;
		vdd-supply = <&s2dos05_ldo2>;
		avdd-supply = <&s2dos05_ldo3>;

		pinctrl-0 = <&touch_irq_state>;
		pinctrl-names = "default";
	};
};

&adsp_pas {
	firmware-name = "qcom/sdm845/Samsung/starqltechn/adsp.mbn";

	status = "okay";
};

&lpasscc {
	status = "okay";
};

&sound {
	compatible = "qcom,sdm845-sndcard";
	model = "Samsung Galaxy S9";
	pinctrl-0 = <&quat_mi2s_active &quat_mi2s_sd0_active &quat_mi2s_sd1_active>;
	pinctrl-names = "default";
	status = "okay";

	audio-routing = "RX_BIAS", "MCLK",
			"AMIC2", "MIC BIAS2",	/* Headset Mic */
			"AMIC3", "MIC BIAS2",	/* FM radio left Tx */
			"AMIC4", "MIC BIAS2",	/* FM radio right Tx */
			"DMIC0", "MCLK",	/* Bottom Mic */
			"DMIC0", "MIC BIAS1",
			"DMIC2", "MCLK",	/* Top Mic */
			"DMIC2", "MIC BIAS3";

	mm1-dai-link {
		link-name = "MultiMedia1";

		cpu {
			sound-dai = <&q6asmdai MSM_FRONTEND_DAI_MULTIMEDIA1>;
		};
	};

	mm2-dai-link {
		link-name = "MultiMedia2";

		cpu {
			sound-dai = <&q6asmdai MSM_FRONTEND_DAI_MULTIMEDIA2>;
		};
	};

	mm3-dai-link {
		link-name = "MultiMedia3";

		cpu {
			sound-dai = <&q6asmdai MSM_FRONTEND_DAI_MULTIMEDIA3>;
		};
	};

	mm4-dai-link {
		link-name = "MultiMedia4";

		cpu {
			sound-dai = <&q6asmdai MSM_FRONTEND_DAI_MULTIMEDIA4>;
		};
	};

	mm5-dai-link {
		link-name = "MultiMedia5";

		cpu {
			sound-dai = <&q6asmdai MSM_FRONTEND_DAI_MULTIMEDIA5>;
		};
	};

	mm6-dai-link {
		link-name = "MultiMedia6";

		cpu {
			sound-dai = <&q6asmdai MSM_FRONTEND_DAI_MULTIMEDIA6>;
		};
	};

	voicemmode1-dai-link {
		link-name = "VoiceMMode1";
		cpu {
			sound-dai = <&q6voicedai VOICEMMODE1>;
		};
	};

	speaker-dai-link {
		link-name = "Speaker Playback";
		codec {
			sound-dai = <&max98512_codec>;
		};

		cpu {
			sound-dai = <&q6afedai QUATERNARY_MI2S_RX>;
		};

		platform {
			sound-dai = <&q6routing>;
		};
	};

	slim-dai-link {
		link-name = "SLIM Playback 1";

		codec {
			sound-dai = <&wcd9340 AIF1_PB>;
		};

		cpu {
			sound-dai = <&q6afedai SLIMBUS_0_RX>;
		};

		platform {
			sound-dai = <&q6routing>;
		};
	};

	slimcap-dai-link {
		link-name = "SLIM Capture 1";

		codec {
			sound-dai = <&wcd9340 AIF1_CAP>;
		};

		cpu {
			sound-dai = <&q6afedai SLIMBUS_0_TX>;
		};

		platform {
			sound-dai = <&q6routing>;
		};
	};

	slim2-dai-link {
		link-name = "SLIM Playback 2";

		codec {
			sound-dai = <&wcd9340 AIF2_PB>;
		};

		cpu {
			sound-dai = <&q6afedai SLIMBUS_1_RX>;
		};

		platform {
			sound-dai = <&q6routing>;
		};
	};

	slimcap2-dai-link {
		link-name = "SLIM Capture 2";

		codec {
			sound-dai = <&wcd9340 AIF2_CAP>;
		};

		cpu {
			sound-dai = <&q6afedai SLIMBUS_1_TX>;
		};

		platform {
			sound-dai = <&q6routing>;
		};
	};

	slimcap3-dai-link {
		link-name = "SLIM Capture 3";

		codec {
			sound-dai = <&wcd9340 AIF3_CAP>;
		};

		cpu {
			sound-dai = <&q6afedai SLIMBUS_2_TX>;
		};

		platform {
			sound-dai = <&q6routing>;
		};
	};
};

&q6afedai {
	dai@22 {
		reg = <22>;
		qcom,sd-lines = <1>;
	};

	dai@23 {
		reg = <23>;
		qcom,sd-lines = <0>;
	};
};

&q6asmdai {
	dai@0 {
		reg = <0>;
	};

	dai@1 {
		reg = <1>;
	};

	dai@2 {
		reg = <2>;
	};

	dai@3 {
		reg = <3>;
	};

	dai@4 {
		reg = <4>;
	};

	dai@5 {
		reg = <5>;
	};
};

&q6cvp {
	status = "okay";
};

&q6cvs {
	status = "okay";
};

&q6mvm {
	status = "okay";
};

&wcd9340 {
	reset-gpios = <&tlmm 64 GPIO_ACTIVE_HIGH>;
	vdd-buck-supply = <&vreg_s4a_1p8>;
	vdd-buck-sido-supply = <&vreg_s4a_1p8>;
	vdd-tx-supply = <&vreg_s4a_1p8>;
	vdd-rx-supply = <&vreg_s4a_1p8>;
	vdd-io-supply = <&vreg_s4a_1p8>;
	qcom,micbias1-microvolt = <1800000>;
	qcom,micbias2-microvolt = <2700000>;
	qcom,micbias3-microvolt = <1800000>;
	qcom,micbias4-microvolt = <1800000>;
};

&mss_pil {
	firmware-name = "qcom/sdm845/Samsung/starqltechn/mba.mbn",
			"qcom/sdm845/Samsung/starqltechn/modem.mbn";

	status = "okay";
};

&ipa {
	qcom,gsi-loader = "self";
	memory-region = <&ipa_fw_mem>;
	firmware-name = "qcom/sdm845/Samsung/starqltechn/ipa_fws.mbn";

	status = "okay";
};

&slpi_pas {
	firmware-name = "qcom/sdm845/Samsung/starqltechn/slpi.mbn";
	cx-supply = <&slpi_regulator>;

	pinctrl-0 = <&slpi_ldo_active_state>;
	pinctrl-1 = <&slpi_ldo_sleep_state>;
	pinctrl-names = "default", "sleep";

	status = "okay";
};

&usb_1 {
	status = "okay";
};

&usb_1_dwc3 {
	dr_mode = "otg";
	usb-role-switch;
};

&usb_1_dwc3_hs {
	remote-endpoint = <&max77705_typec_hs>;
};

&usb_1_hsphy {
	vdd-supply = <&vdda_usb1_ss_core>;
	vdda-pll-supply = <&vdda_qusb_hs0_1p8>;
	vdda-phy-dpdm-supply = <&vdda_qusb_hs0_3p1>;

	qcom,imp-res-offset-value = <8>;
	qcom,hstx-trim-value = <QUSB2_V2_HSTX_TRIM_21_6_MA>;
	qcom,preemphasis-level = <QUSB2_V2_PREEMPHASIS_5_PERCENT>;
	qcom,preemphasis-width = <QUSB2_V2_PREEMPHASIS_WIDTH_HALF_BIT>;
	status = "okay";
};

&usb_1_qmpphy {
	vdda-phy-supply = <&vdda_usb1_ss_1p2>;
	vdda-pll-supply = <&vdda_usb1_ss_core>;
	status = "okay";
};

&pm8998_resin {
	linux,code = <KEY_VOLUMEDOWN>;
	status = "okay";
};

/*
 * The PMIC's clock dividers drive a set of outputs that are wired out through
 * alternate functions on the PMIC's own GPIOs -- GPIO13 in func1 here, which
 * feeds the FM tuner's reference. The downstream kernel configures all three
 * of these blocks at boot via qcom,clkdiv-init-freq, so on a stock kernel the
 * clock is simply always running; mainline registers them but leaves them off
 * until a consumer enables one, which is why the tuner claims them below.
 */
&pm8998_lsid0 {
	pm8998_clkdiv: clock-controller@5b00 {
		compatible = "qcom,spmi-clkdiv";
		reg = <0x5b00>;
		clocks = <&xo_board>;
		clock-names = "xo";
		#clock-cells = <1>;
		qcom,num-clkdivs = <3>;

		/* Match the 19.2 MHz the downstream kernel programs. */
		assigned-clocks = <&pm8998_clkdiv 1>, <&pm8998_clkdiv 2>,
				  <&pm8998_clkdiv 3>;
		assigned-clock-rates = <19200000>, <19200000>, <19200000>;
	};
};

&pm8998_gpios {
	fm_sleep_clk_state: fm-sleep-clk-state {
		pins = "gpio13";
		function = "func1";
		bias-disable;
		power-source = <0>;
		output-low;
	};

	pmic_int_default: pmic-int-default-state {
		pins = "gpio11";
		function = "normal";
		input-enable;
		bias-disable;
		power-source = <0>;
	};
};

&tlmm {
	gpio-reserved-ranges = <27 4>, /* SPI (eSE - embedded Secure Element) */
			       <85 4>; /* SPI (fingerprint reader) */

	dp_aux_default: dp-aux-default-state {
		pins = "gpio7", "gpio100";
		function = "gpio";
		drive-strength = <8>;
		bias-disable;
	};

	pcie0_default_state: pcie0-default-state {
		clkreq-pins {
			pins = "gpio36";
			function = "pci_e0";
			bias-pull-up;
		};

		reset-n-pins {
			pins = "gpio35";
			function = "gpio";
			drive-strength = <2>;
			output-low;
			bias-pull-down;
		};

		wake-n-pins {
			pins = "gpio116";
			function = "gpio";
			drive-strength = <2>;
			bias-pull-down;
		};
	};

	cam_rear_mclk_active: cam-rear-mclk-active-state {
		pins = "gpio13";
		function = "cam_mclk";
		drive-strength = <4>;
		bias-disable;
	};

	cam_rear_mclk_suspend: cam-rear-mclk-suspend-state {
		pins = "gpio13";
		function = "cam_mclk";
		drive-strength = <4>;
		bias-pull-down;
	};

	cam_rear_rst_active: cam-rear-rst-active-state {
		pins = "gpio25";
		function = "gpio";
		drive-strength = <2>;
		bias-disable;
	};

	cam_rear_rst_suspend: cam-rear-rst-suspend-state {
		pins = "gpio25";
		function = "gpio";
		drive-strength = <2>;
		bias-pull-down;
		output-low;
	};

	cam_front_mclk_active: cam-front-mclk-active-state {
		pins = "gpio15";
		function = "cam_mclk";
		drive-strength = <4>;
		bias-disable;
	};

	cam_front_mclk_suspend: cam-front-mclk-suspend-state {
		pins = "gpio15";
		function = "cam_mclk";
		drive-strength = <4>;
		bias-pull-down;
	};

	cam_front_rst_active: cam-front-rst-active-state {
		pins = "gpio12";
		function = "gpio";
		drive-strength = <2>;
		bias-disable;
	};

	cam_front_rst_suspend: cam-front-rst-suspend-state {
		pins = "gpio12";
		function = "gpio";
		drive-strength = <2>;
		bias-pull-down;
		output-low;
	};

	cam_iris_mclk_active: cam-iris-mclk-active-state {
		pins = "gpio16";
		function = "cam_mclk";
		drive-strength = <4>;
		bias-disable;
	};

	cam_iris_mclk_suspend: cam-iris-mclk-suspend-state {
		pins = "gpio16";
		function = "cam_mclk";
		drive-strength = <4>;
		bias-pull-down;
	};

	cam_iris_rst_active: cam-iris-rst-active-state {
		pins = "gpio44";
		function = "gpio";
		drive-strength = <2>;
		bias-disable;
	};

	cam_iris_rst_suspend: cam-iris-rst-suspend-state {
		pins = "gpio44";
		function = "gpio";
		drive-strength = <2>;
		bias-pull-down;
		output-low;
	};

	cam_fled_strobe_state: cam-fled-strobe-state {
		pins = "gpio21", "gpio22", "gpio43";
		function = "gpio";
		drive-strength = <2>;
		bias-pull-down;
		output-low;
	};

	dsi_default: dsi-default-state {
		pins = "gpio6";
		function = "gpio";
		drive-strength = <8>;
		bias-disable;
	};

	dsi_suspend: dsi-suspend-state {
		pins = "gpio6";
		function = "gpio";
		drive-strength = <2>;
		bias-pull-down;
	};

	dsi_te: dsi-te-state {
		pins = "gpio10";
		function = "mdp_vsync";
		drive-strength = <2>;
		bias-pull-down;
	};

	i2c1_sda_state: i2c1-sda-state {
		pins = "gpio23";
		function = "gpio";
		drive-strength = <2>;
		bias-disable;
	};

	i2c1_scl_state: i2c1-scl-state {
		pins = "gpio24";
		function = "gpio";
		drive-strength = <2>;
		bias-disable;
	};

	i2c2_sda_state: i2c2-sda-state {
		pins = "gpio11";
		function = "gpio";
		drive-strength = <2>;
		bias-disable;
	};

	i2c2_scl_state: i2c2-scl-state {
		pins = "gpio74";
		function = "gpio";
		drive-strength = <2>;
		bias-disable;
	};

	i2c21_sda_state: i2c21-sda-state {
		pins = "gpio127";
		function = "gpio";
		drive-strength = <2>;
		bias-disable;
	};

	i2c21_scl_state: i2c21-scl-state {
		pins = "gpio128";
		function = "gpio";
		drive-strength = <2>;
		bias-disable;
	};

	i2c22_sda_state: i2c22-sda-state {
		pins = "gpio123";
		function = "gpio";
		drive-strength = <2>;
		bias-disable;
	};

	i2c22_scl_state: i2c22-scl-state {
		pins = "gpio124";
		function = "gpio";
		drive-strength = <2>;
		bias-disable;
	};

	fm_i2c_sda_state: fm-i2c-sda-state {
		pins = "gpio103";
		function = "gpio";
		drive-strength = <2>;
		bias-disable;
	};

	fm_i2c_scl_state: fm-i2c-scl-state {
		pins = "gpio104";
		function = "gpio";
		drive-strength = <2>;
		bias-disable;
	};

	fm_int_state: fm-int-state {
		pins = "gpio145";
		function = "gpio";
		drive-strength = <2>;
		bias-pull-down;
	};

	motor_pwm_default_state: motor-pwm-active-state {
		pins = "gpio57";
		function = "gcc_gp1";
		drive-strength = <2>;
		bias-disable;
		output-high;
	};

	motor_pwm_suspend_state: motor-pwm-suspend-state {
		pins = "gpio57";
		function = "gpio";
		drive-strength = <2>;
		bias-disable;
		output-low;
	};

	sdc2_clk_state: sdc2-clk-state {
		pins = "sdc2_clk";
		bias-disable;

		/*
		 * It seems that mmc_test reports errors if drive
		 * strength is not 16 on clk, cmd, and data pins.
		 */
		drive-strength = <16>;
	};

	sdc2_cmd_state: sdc2-cmd-state {
		pins = "sdc2_cmd";
		bias-pull-up;
		drive-strength = <16>;
	};

	sdc2_data_state: sdc2-data-state {
		pins = "sdc2_data";
		bias-pull-up;
		drive-strength = <16>;
	};

	sd_card_det_n_state: sd-card-det-n-state {
		pins = "gpio126";
		function = "gpio";
		bias-pull-up;
	};

	slpi_ldo_active_state: slpi-ldo-active-state {
		pins = "gpio8";
		function = "gpio";
		drive-strength = <2>;
		bias-disable;
		output-high;
	};

	slpi_ldo_sleep_state: slpi-ldo-sleep-state {
		pins = "gpio8";
		function = "gpio";
		drive-strength = <2>;
		bias-disable;
		output-low;
	};

	i2c18_sda_state: i2c18-sda-state {
		pins = "gpio62";
		function = "gpio";
		drive-strength = <2>;
		bias-disable;
	};

	i2c18_scl_state: i2c18-scl-state {
		pins = "gpio63";
		function = "gpio";
		drive-strength = <2>;
		bias-disable;
	};

	touch_irq_state: touch-irq-state {
		pins = "gpio120";
		function = "gpio";
		bias-disable;
	};
};

&qup_i2c11_default {
	drive-strength = <2>;
	bias-disable;
};
